# xusb3_model: IP-XACT component
VLNV IcronTechnologies:IcronTechnologies:xusb3_model:1.0

## Parameters
addr_width = 9
bus_width = 32

## Bus interfaces (logical=physical port)
default_map: slave AGNISYS:AGNISYS:APB:1.0, memory map xusb3map
  pclk=pclk, presetn=presetn, psel=psel, penable=penable, pwrite=pwrite, pprot=pprot, pstrb=pstrb, pwdata=pwdata, paddr=paddr, pready=pready, prdata=prdata, pslverr=pslverr

## Ports
in pclk
in presetn
in psel
in penable
in pwrite
in pprot[2:0]
in pstrb[(bus_width div 8 )-1:0]
in pwdata[bus_width -1:0]
in paddr[addr_width -1:0]
out pready
out prdata[bus_width -1:0]
out pslverr
out xusb3_regsversion_major_r[7:0]
out xusb3_regsversion_minor_r[7:0]
out xusb3_regsversion_patch_r[7:0]
out xusb3_regsconfiguration_enb
out xusb3_regsconfiguration_rx_buff_near_full_limit_r[7:0]
out xusb3_regsconfiguration_upp_bypass_r
in xusb3_regsconfiguration_upp_is_present_in
in xusb3_regsconfiguration_upp_is_present_in_enb
out xusb3_regsconfiguration_split_dp_wait_time_r[15:0]
out xusb3_regsconfiguration_split_dp_mode_r
out xusb3_regsconfiguration_allow_rx_buff_fill_r
out xusb3_regsconfiguration_drop_itp_pkts_r
out xusb3_regsconfiguration_upstream_port_r
out xusb3_regscontrol_enb
out xusb3_regscontrol_remove_crdts_r
out xusb3_regsrx_partner_fifo_write_engine_config0_clear_enb
out xusb3_regsrx_partner_fifo_write_engine_config0_clear_wclr_r
out xusb3_regsrx_partner_fifo_write_engine_config0_mode_enb
out xusb3_regsrx_partner_fifo_write_engine_config0_mode_drp_on_sop_r
out xusb3_regsrx_partner_fifo_write_engine_config0_mode_drp_on_pkt_err_r
out xusb3_regsrx_partner_fifo_write_engine_config0_mode_pkt_strm_r
out xusb3_regsrx_partner_fifo_write_engine_config0_mode_flw_ctrl_en_r
out xusb3_regsrx_partner_fifo_write_engine_config0_notify_limit_enb
out xusb3_regsrx_partner_fifo_write_engine_config0_notify_limit_ntfy_lmt_r[31:0]
out xusb3_regsrx_partner_fifo_write_engine_stats0_rd2clr_config_rd_valid_out
out xusb3_regsrx_partner_fifo_write_engine_stats0_rd2clr_config_wr_valid_out
out xusb3_regsrx_partner_fifo_write_engine_stats0_nfifo_dcount_rd_valid_out
out xusb3_regsrx_partner_fifo_write_engine_stats0_pfifo_dcount_rd_valid_out
out xusb3_regsrx_partner_fifo_write_engine_stats0_pkt_max_byte_cnt_err_rd_valid_out
out xusb3_regsrx_partner_fifo_write_engine_stats0_fifo_full_err_rd_valid_out
out xusb3_regsrx_partner_fifo_write_engine_stats0_pkt_err_rd_valid_out
out xusb3_regsrx_partner_fifo_write_engine_stats0_pkt_sop_err_rd_valid_out
out xusb3_regsrx_partner_fifo_write_engine_stats0_wflush_act_rd_valid_out
out xusb3_regsrx_partner_fifo_write_engine_stats0_drp_pkt_rd_rd_valid_out
out xusb3_regsrx_partner_fifo_write_engine_stats0_drp_pkt_wr_rd_valid_out
out xusb3_regsrx_partner_fifo_write_engine_stats0_flow_ctrl_rd_valid_out
out xusb3_regsrx_partner_fifo_read_engine_config0_clear_enb
out xusb3_regsrx_partner_fifo_read_engine_config0_clear_rclr_r
out xusb3_regsrx_partner_fifo_read_engine_stats0_rd2clr_config_rd_valid_out
out xusb3_regsrx_partner_fifo_read_engine_stats0_rd2clr_config_wr_valid_out
out xusb3_regsrx_partner_fifo_read_engine_stats0_rflush_act_rd_valid_out
out xusb3_regsrx_partner_fifo_read_engine_stats0_drp_pkt_rd_valid_out
out xusb3_regsrx_partner_fifo_read_engine_stats0_flow_ctrl_rd_valid_out
out xusb3_regsstats0_rd2clr_config_rd_valid_out
out xusb3_regsstats0_rd2clr_config_wr_valid_out
out xusb3_regsstats0_link_partner_ptp_violated_rd_valid_out
out xusb3_regsstats0_from_phy_in_sop_rd_valid_out
out xusb3_regsstats0_from_phy_in_eop_rd_valid_out
out xusb3_regsstats0_to_link_out_sop_rd_valid_out
out xusb3_regsstats0_to_link_out_eop_rd_valid_out
out xusb3_regsstats0_from_link_in_sop_rd_valid_out
out xusb3_regsstats0_from_link_in_eop_rd_valid_out
out xusb3_regsstats0_unknown_pkt_drp_rd_valid_out
out xusb3_regsstats0_dwn_stream_busy_drp_rd_valid_out
out xusb3_regsstats0_drop_lone_dpp_rd_valid_out
out xusb3_regsstats0_rcvd_lone_dph_rd_valid_out
out xusb3_regsstats0_timedout_2join_dpp_rd_valid_out
out xusb3_regsstats0_not_rdy_pkt_drp_rd_valid_out
out xusb3_regsptp_guard_2core_config0_fix_ptp_violations_enb
out xusb3_regsptp_guard_2core_config0_fix_ptp_violations_activate_r
out xusb3_regsptp_guard_2core_config0_max_cycles_enb
out xusb3_regsptp_guard_2core_config0_max_cycles_max_cycle_mode_r[3:0]
out xusb3_regsptp_guard_2core_config0_max_cycles_max_cycles_r[15:0]
out xusb3_regsptp_guard_2core_stats0_rd2clr_config_rd_valid_out
out xusb3_regsptp_guard_2core_stats0_rd2clr_config_wr_valid_out
out xusb3_regsptp_guard_2core_stats0_missing_sop_err_rd_valid_out
out xusb3_regsptp_guard_2core_stats0_missing_eop_err_rd_valid_out
out xusb3_regsptp_guard_2core_stats0_max_cycle_err_rd_valid_out
out xusb3_regsbuff_2ulp_control_enb
out xusb3_regsbuff_2ulp_control_clr_r
out xusb3_regsbuff_2ulp_stats0_rd2clr_config_rd_valid_out
out xusb3_regsbuff_2ulp_stats0_rd2clr_config_wr_valid_out
out xusb3_regsbuff_2ulp_stats0_nfifo_dcount_rd_valid_out
out xusb3_regsbuff_2ulp_stats0_pfifo_dcount_rd_valid_out
out xusb3_regsbuff_2upp_control_enb
out xusb3_regsbuff_2upp_control_clr_r
out xusb3_regsbuff_2upp_stats0_rd2clr_config_rd_valid_out
out xusb3_regsbuff_2upp_stats0_rd2clr_config_wr_valid_out
out xusb3_regsbuff_2upp_stats0_nfifo_scount_rd_valid_out
out xusb3_regsbuff_2upp_stats0_pfifo_scount_rd_valid_out

## Address spaces and blocks
xusb3map.xusb3: base 0x000, range 0x200, width 32

## Registers
Registers are 32-bit, read-only, reset 0x0 unless marked. A register's access mark holds for its fields unless they carry their own. Offsets are from the block's base; lines under a group give offsets from that group; [hi:lo] are bit positions; {n}, {i} and the like mark numbered series; 'fields as' and 'values as' point back to an identical list; <NAME> marks a mode.

## xusb3map.xusb3 — XUSB3 Registers
Base 0x00000000
0x00 version reset 0x40000 — 2.0.0: Added new clock for ITP Manager Support. 3.0.0: Added new reset domain for UPP and separated from XUSB3 3.1.0: Changed the Interrupt Pending to avoid blocking the register update when enable is 0 3.2.0: Added pending_irq register 3.3.0: Bug fix and register name change 3.4.0: Bug fix in RX Partner Manager 3.5.0: Add sensitivity to DPH and DPP in RX Partner, and number of other enhancements 3.5.1: Removed back pressure to MCA that resulted timing loop, and removed mark_debug to improve timing 3.5.2: put back the back pressure to MCA again but enabled write pipeline for PFIFO to address timing loop 4.0.0: Add elastic buffer registers and bug fix for purging data
  [23:16] major — Major version
  [15:8] minor — Minor version
  [7:0] patch — Patch version
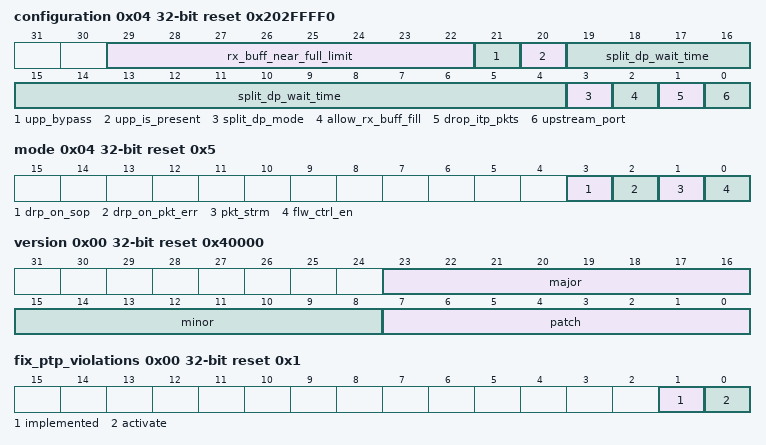
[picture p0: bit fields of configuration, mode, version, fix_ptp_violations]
0x04 configuration access per field reset 0x202FFFF0
  [29:22] rx_buff_near_full_limit rw — The number of cycles limit of the RX Partner FIFO before its maximum value over which the DPP portion of the in data is dropped and only DPH are saved to guard against any lost DPH.
  [21] upp_bypass rw — This register is only valid when upp_is_present=1. When set to 0, it enables the USB Protocol Partner (UPP) logic in the XUSB3 and moves the traffic through the UPP. When set to 1, it bypasses the UPP and the traffic is from USB Link Partner (ULP) to/from core.
  [20] upp_is_present ro — This register shows if the UPP logic has been instantiated in the logic.
  [19:4] split_dp_wait_time rw — Indicates the number of Core Cycles that the RX Partner Manager waits for the DPP portion of a split DP packet to arrive. After this wait, if the DPP does not arrive, the logic will send the DPH portion to the Host and will drop the DPP if it comes later. A value of 0 disables this wait and requires back-2-back DPH and DPP. Note the impact of this value on the USB end-to-end latency on one extreme and on the integrity of the USB DP packet delivery on the other.
  [3] split_dp_mode rw — When 1, it instructs to split the DP USB packets into DPH and DPP packets when sent over the system link as two independent PTP packets. These DPH and DPP PTP packets will join on the other side into the same DP USB in normal operation (not in retry operation)
  [2] allow_rx_buff_fill rw — When 1, it allows the RX Link Partner buffer to accept the partner's packet even if the Link Layer (ULP) is not ready to process these packets yet. The ULP is only ready to process these packets when it is in U0 and has finished the LMP.
  [1] drop_itp_pkts rw — When 1 it instructs the LEX to drop the ITP packets and not send them to REX.
  [0] upstream_port rw — When 1, it indicates the XUSB3 works as an Upstream Port (used in LEX). When 0, it is a Downstream port used in REX.
0x08 control rw
  [0] remove_crdts — When 1, it forces the Link Layer to not issue credit to its USB link partner. This will effectively stop receiving any data or header packets from the link partner. This bit is mainly for debugging and software should not use it under normal system usage.
0x0C rx_partner_fifo group
  0x00 version reset 0x10100 — Version 1.1.0: Added Icron Attributes for stats script generation
    fields as version
  0x04 write_engine group
    0x00 config0 group
      0x00 clear rw — Synchronous clear for the write clock domain
        [0] wclr
      0x04 mode rw reset 0x5
        [3] drp_on_sop — When set, drops the current packet without writing it to the buffer. See Wiki
        [2] drp_on_pkt_err — When set, removes the packet from the buffer without presenting it to the output interface upon the ERR bit being set before the notification point. See Wiki
        [1] pkt_strm — Selects packet based or streaming based behavior. See Wiki
        [0] flw_ctrl_en — Enables the flow control. See Wiki
      0x08 notify_limit rw
        [31:0] ntfy_lmt — Sets the number of words required to be written into the packet FIFO before a notification will be generated. See wiki
    0x0C stats0 group — All the Statistic Registers and their configuration for the Write Engine
      0x00 rd2clr_config rw — Configures if the stats register read by s/w clears the read register. A 1 in any bit configures the h/w to clear the corresponding stats register after a s/w read of that stats register.
        [9] flow_ctrl, [8] drp_pkt_wr, [7] drp_pkt_rd, [6] wflush_act, [5] pkt_sop_err, [4] pkt_err, [3] fifo_full_err, [2] pkt_max_byte_cnt_err, [1] pfifo_dcount, [0] nfifo_dcount
      0x04 nfifo_dcount — Current level for the notification FIFO in the PFIFO
        [15:0] nfifo_dcount — _icron_water_marker_ _icron_no_counter_
      0x08 pfifo_dcount — Current level for the packet FIFO in the PFIFO
        [15:0] pfifo_dcount — _icron_water_marker_ _icron_no_counter_
      0x0C pkt_max_byte_cnt_err — The count for capped packets in PFIFO write engine, as the result of reaching maximum size in the PFIFO
        [7:0] pkt_max_byte_cnt_err
      0x10 fifo_full_err — The count for either of PFIFO or NFIFO being full
        [7:0] fifo_full_err
      0x14 pkt_err — The count of packets tagged to be dropped later in the PFIFO read engine
        [7:0] pkt_err
      0x18 pkt_sop_err — The count of packets flushed in the PFIFO during the SOP phase
        [7:0] pkt_sop_err
      0x1C wflush_act — The count of capped packets in the PFIFO. Note that back-to-back packets are counted as one if they are both capped.
        [7:0] wflush_act — _icron_event_detect_rising_edge_
      0x20 drp_pkt_rd — The count of drop packets flagged to be dropped by the read engine
        [7:0] drp_pkt_rd
      0x24 drp_pkt_wr — The count of drop packets by the write engine
        [7:0] drp_pkt_wr
      0x28 flow_ctrl — The count of the clock cycles the DRDY is asserted low resulting in flow control
        [15:0] flow_ctrl
  0x3C read_engine group
    0x00 config0 group
      0x00 clear rw — Synchronous clear for the read clock domain
        [0] rclr
    0x04 stats0 group — All the Statistic Registers and their configuration for the Read Engine
      0x00 rd2clr_config rw — Configures if the stats register read by s/w clears the read register. A 1 in any bit configures the h/w to clear the corresponding stats register after a s/w read of that stats register.
        [2] flow_ctrl, [1] drp_pkt, [0] rflush_act
      0x04 rflush_act — The counts of number of packets flushed from the PFIFO.
        [7:0] rflush_act — _icron_event_detect_rising_edge_
      0x08 drp_pkt — The counts of drop packet in the PFIFO read engine
        [7:0] drp_pkt
      0x0C flow_ctrl — The count of the clock cycles the DRDY is asserted low resulting in flow control
        [15:0] flow_ctrl
0x5C stats0 group — All the Statistic Registers and their configuration
  0x00 rd2clr_config rw — Configures if the stats register read by s/w clears the read register. A 1 in any bit configures the h/w to clear the corresponding stats register after a s/w read of that stats register.
    [12] not_rdy_pkt_drp, [11] timedout_2join_dpp, [10] rcvd_lone_dph, [9] drop_lone_dpp, [8] dwn_stream_busy_drp, [7] unknown_pkt_drp, [6] from_link_in_eop, [5] from_link_in_sop, [4] to_link_out_eop, [3] to_link_out_sop, [2] from_phy_in_eop, [1] from_phy_in_sop, [0] link_partner_ptp_violated
  0x04 link_partner_ptp_violated — Count the number of PTP Protocol Violation in the Link Partner Manager
    [7:0] link_partner_ptp_violated — _icron_event_detect_rising_edge_
  0x08 from_phy_in_sop — Count the number of PTP sop from USB PHY
  0x0C from_phy_in_eop — Count the number of PTP eop from USB PHY
  0x10 to_link_out_sop — Count the number of PTP sop to the Eth Link path
  0x14 to_link_out_eop — Count the number of PTP eop to the Eth Link path
  0x18 from_link_in_sop — Count the number of PTP sop from the Eth Link path
  0x1C from_link_in_eop — Count the number of PTP eop from the Eth Link path
  0x20 unknown_pkt_drp — Count of unknown packets dropped at the TX Link Partner Manager
    [15:0] unknown_pkt_drp
  0x24 dwn_stream_busy_drp — Count of the DPP portion of DP packet being truncated when the TX Link Partner Manager downstream (MCA) is flow controlling
    [15:0] dwn_stream_busy_drp
  0x28 drop_lone_dpp — Count of the lone (not preceded with DPH) DPP received at the RX Link Partner Manager that were dropped
    [15:0] drop_lone_dpp
  0x2C rcvd_lone_dph — Count of the lone DPH (not followed by DPP) received at the RX Link Partner Manager
    [15:0] rcvd_lone_dph
  0x30 timedout_2join_dpp — Count of the number of times that a DPH was received and it was not followed by a DPP after exhausting the wait period as instructed in the Configuration Register
    [15:0] timedout_2join_dpp
  0x34 not_rdy_pkt_drp — Count of the number of times a PTP packet was received from the Link Partner at the RX and it was dropped as the ULP core is not ready to process yet. The ULP core is only ready to process these packets when it is in U0 and has finished the LMP. This count only will show when allow_rx_buff_fill register in the Configuration is set to 1'b0. Otherwise, PTP packets are not dropped and are written into the buffer.
    [15:0] not_rdy_pkt_drp
0x94 ptp_guard_2core group
  0x00 version reset 0x30300 — 3.1.0: Fixed bug in Max Cycle Error where in certain mode the cycles were included in the count 3.2.0: Changed the Interrupt Pending to avoid blocking the register update when enable is 0 3.3.0: Added pending_irq register
    fields as version
  0x04 config0 group
    0x00 fix_ptp_violations access per field reset 0x1
      [1] implemented ro — This is the synthesis parameter value used. When 1, it shows the PTP Guard fix logic has been implemented
      [0] activate rw — When 1, and if the fix logic is implemented, it instructs the PTP Guard to fix the PTP violations it detects (and reports). Note that there is a synthesis parameter to generate the "fix" logic or not When 0, no attempt is done to fix (even if the logic exists) and the PTP Guard will only work as a monitor and reports the violations detected. For full details of the operation, what violations are detected and fixed, and how the fix is done, see the wiki.
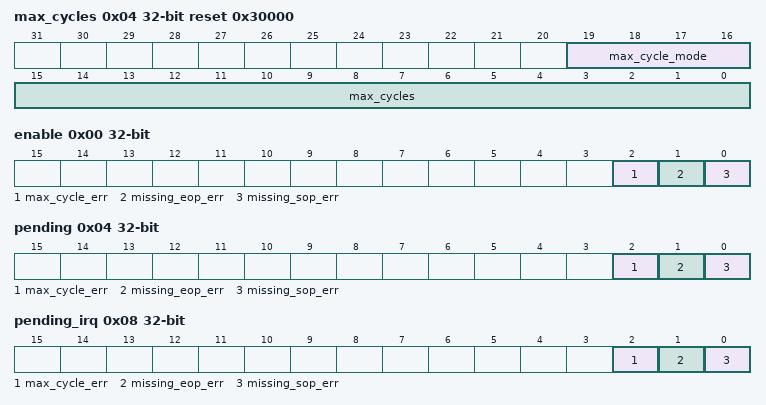
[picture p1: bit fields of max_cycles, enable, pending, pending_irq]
    0x04 max_cycles rw reset 0x30000
      [19:16] max_cycle_mode — This configures the mode of counting towards max_cycles: 0x0: All PTP cycles are included in the count 0x1: PTP cycles with backpressure (drdy=1'b0) are excluded from the count 0x2: PTP cycles with wait (srdy=1'b0) are excluded from the count 0x3: PTP cycles with either backpressure or wait are excluded from the count. Hence, only "absorbed" PTP cycles are included in the count Other mode values are reserved
      [15:0] max_cycles — Sets the maximum number of clock cycles the PTP packet can last between its sop and eop taking into account the max_cycle_mode When set to 0, it instructs the logic not to fix this violation (when the fix logic is available). However, the monitor will still issue a violation when the cycle count reaches its maximum and rollover.
  0x0C stats0 group — All the Statistic Registers and their configuration
    0x00 rd2clr_config rw — Configures if the stats register read by s/w clears the read register. A 1 in any bit configures the h/w to clear the corresponding stats register after a s/w read of that stats register.
      [2] max_cycle_err, [1] missing_eop_err, [0] missing_sop_err
    0x04 missing_sop_err — Counts the number of PTP violations due to missing sop where the srdy was asserted without a prior sop assertion
      [15:0] missing_sop_err
    0x08 missing_eop_err — Counts the number of PTP violations due to missing eop where the PTP had been started but a new sop is seen without ending the previously started PTP
      [15:0] missing_eop_err
    0x0C max_cycle_err — Counts the number of PTP violations due to reaching the maximum allowed cycles after starting a new PTP
      [15:0] max_cycle_err
  0x1C irq0 group — Define the IRQ group
    0x00 enable rw — The enable for the actual interrupt signals. Writing a 1 enables the interrupt.
      [2] max_cycle_err — Fires on PTP violations due to reaching the maximum allowed cycles after starting a new PTP
      [1] missing_eop_err — Fires on PTP violations due to missing eop where the PTP had been started but a new sop is seen without ending the previously started PTP
      [0] missing_sop_err — Fires on PTP violations due to missing sop where the srdy was asserted without a prior sop assertion
    0x04 pending rw — The actual interrupt(s) that has triggered. Write a 1 to clear.
      [2] max_cycle_err write-1-clears, [1] missing_eop_err write-1-clears, [0] missing_sop_err write-1-clears
    0x08 pending_irq — Registered version of pending & enable.
      [2] max_cycle_err, [1] missing_eop_err, [0] missing_sop_err
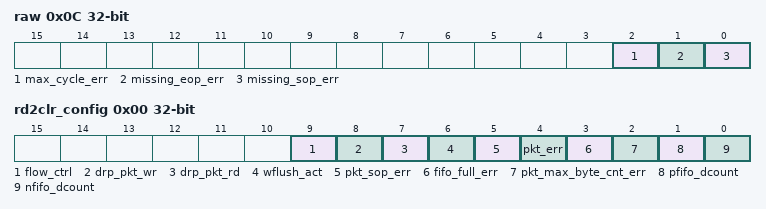
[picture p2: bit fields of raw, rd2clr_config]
    0x0C raw — The status registered values for the interrupt signals, if applicable.
      [2] max_cycle_err — Not used
      [1] missing_eop_err — Not used
      [0] missing_sop_err — Not used
0xC0 buff_2ulp group
  0x00 control rw
    [0] clr — Clear for both clock domains (write and read)
  0x04 stats0 group — All the Statistic Registers and their configuration for the Write Engine
    0x00 rd2clr_config rw — Configures if the stats register read by s/w clears the read register. A 1 in any bit configures the h/w to clear the corresponding stats register after a s/w read of that stats register.
      [1] pfifo_dcount, [0] nfifo_dcount
    0x04 nfifo_dcount — Current level for the notification FIFO in the PFIFO
      [15:0] nfifo_dcount — _icron_water_marker_ _icron_no_counter_
    0x08 pfifo_dcount — Current level for the packet FIFO in the PFIFO
      [15:0] pfifo_dcount — _icron_water_marker_ _icron_no_counter_
0xD0 buff_2upp group
  0x00 control rw
    [0] clr — Clear for both clock domains (write and read)
  0x04 stats0 group — All the Statistic Registers and their configuration for the Read Engine
    0x00 rd2clr_config rw — Configures if the stats register read by s/w clears the read register. A 1 in any bit configures the h/w to clear the corresponding stats register after a s/w read of that stats register.
      [1] pfifo_scount, [0] nfifo_scount
    0x04 nfifo_scount — Current level for the notification FIFO in the PFIFO
      [15:0] nfifo_scount — _icron_water_marker_ _icron_no_counter_
    0x08 pfifo_scount — Current level for the packet FIFO in the PFIFO
      [15:0] pfifo_scount — _icron_water_marker_ _icron_no_counter_
0xE0 irq0 group — Define the IRQ group
  0x00 enable rw — The enable for the actual interrupt signals. Writing a 1 enables the interrupt.
    [0] link_partner_ptp_violated — Fires on PTP Protocol Violation in the Link Partner Manager
  0x04 pending rw — The actual interrupt(s) that has triggered. Write a 1 to clear.
    [0] link_partner_ptp_violated write-1-clears — Fires on PTP Protocol Violation in the Link Partner Manager
  0x08 pending_irq — Registered version of pending & enable
    fields as irq0.enable
  0x0C raw — The status registered values for the interrupt signals, if applicable.
    [0] link_partner_ptp_violated — Not used
